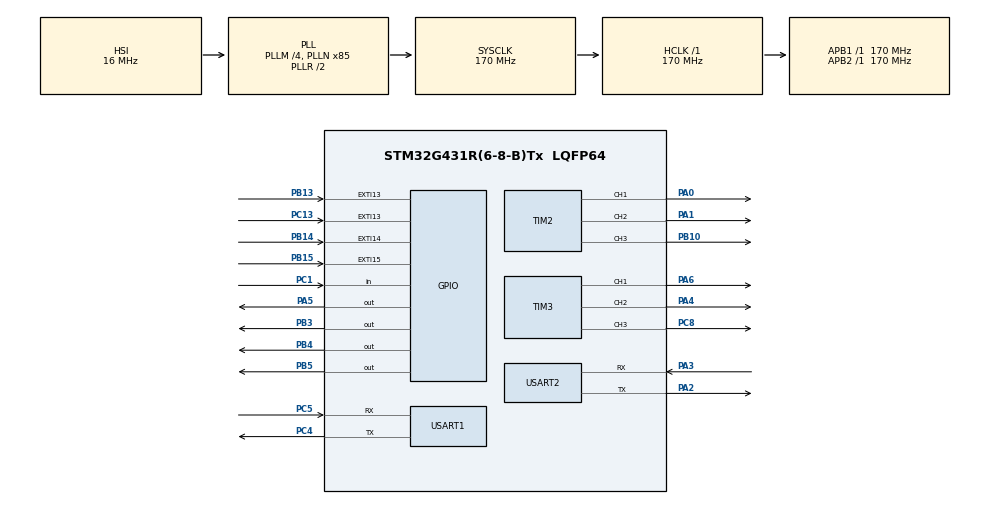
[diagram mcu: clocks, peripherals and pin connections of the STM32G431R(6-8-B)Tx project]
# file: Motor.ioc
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Dma.Request0=USART1_TX
Dma.Request1=USART1_RX
Dma.USART1_RX.1.Direction=DMA_PERIPH_TO_MEMORY
Dma.USART1_RX.1.EventEnable=DISABLE
Dma.USART1_RX.1.Instance=DMA1_Channel2
Dma.USART1_RX.1.MemDataAlignment=DMA_MDATAALIGN_BYTE
Dma.USART1_RX.1.MemInc=DMA_MINC_ENABLE
Dma.USART1_RX.1.Mode=DMA_NORMAL
Dma.USART1_RX.1.PeriphDataAlignment=DMA_PDATAALIGN_BYTE
Dma.USART1_RX.1.PeriphInc=DMA_PINC_DISABLE
Dma.USART1_RX.1.Polarity=HAL_DMAMUX_REQ_GEN_RISING
Dma.USART1_RX.1.Priority=DMA_PRIORITY_LOW
Dma.USART1_RX.1.RequestNumber=1
Dma.USART1_RX.1.SignalID=NONE
Dma.USART1_RX.1.SyncEnable=DISABLE
Dma.USART1_RX.1.SyncPolarity=HAL_DMAMUX_SYNC_NO_EVENT
Dma.USART1_RX.1.SyncRequestNumber=1
Dma.USART1_RX.1.SyncSignalID=NONE
Dma.USART1_TX.0.Direction=DMA_MEMORY_TO_PERIPH
Dma.USART1_TX.0.EventEnable=DISABLE
Dma.USART1_TX.0.Instance=DMA1_Channel1
Dma.USART1_TX.0.MemDataAlignment=DMA_MDATAALIGN_BYTE
Dma.USART1_TX.0.MemInc=DMA_MINC_ENABLE
Dma.USART1_TX.0.Mode=DMA_NORMAL
Dma.USART1_TX.0.PeriphDataAlignment=DMA_PDATAALIGN_BYTE
Dma.USART1_TX.0.PeriphInc=DMA_PINC_DISABLE
Dma.USART1_TX.0.Polarity=HAL_DMAMUX_REQ_GEN_RISING
Dma.USART1_TX.0.Priority=DMA_PRIORITY_LOW
Dma.USART1_TX.0.RequestNumber=1
Dma.USART1_TX.0.SignalID=NONE
Dma.USART1_TX.0.SyncEnable=DISABLE
Dma.USART1_TX.0.SyncPolarity=HAL_DMAMUX_SYNC_NO_EVENT
Dma.USART1_TX.0.SyncRequestNumber=1
Dma.USART1_TX.0.SyncSignalID=NONE
Mcu.Family=STM32G4
Mcu.Name=STM32G431R(6-8-B)Tx
Mcu.Package=LQFP64
NUCLEO-G431RB.BUTTON=1
NUCLEO-G431RB.LD1=true
NUCLEO-G431RB.VCP=true
NVIC.DMA1_Channel1_IRQn=true\:0\:0\:false\:false\:true\:false\:true\:true
NVIC.DMA1_Channel2_IRQn=true\:0\:0\:false\:false\:true\:false\:true\:true
NVIC.EXTI15_10_IRQn=true\:0\:0\:false\:false\:true\:false\:true\:true
NVIC.PriorityGroup=NVIC_PRIORITYGROUP_4
NVIC.TIM2_IRQn=true\:0\:0\:false\:false\:true\:true\:true\:true
NVIC.TIM3_IRQn=true\:0\:0\:false\:false\:true\:true\:true\:true
NVIC.TIM6_DAC_IRQn=true\:0\:0\:false\:false\:true\:true\:true\:true
NVIC.USART1_IRQn=true\:0\:0\:false\:false\:true\:true\:true\:true
PA0.Signal=S_TIM2_CH1
PA1.Signal=S_TIM2_CH2
PA13.GPIO_Label=T_SWDIO
PA13.Signal=SYS_JTMS-SWDIO
PA14.GPIO_Label=T_SWCLK
PA14.Signal=SYS_JTCK-SWCLK
PA2.Mode=Asynchronous
PA2.Signal=USART2_TX
PA3.Mode=Asynchronous
PA3.Signal=USART2_RX
PA4.Signal=S_TIM3_CH2
PA5.Signal=GPIO_Output
PA6.Signal=S_TIM3_CH1
PB10.Signal=S_TIM2_CH3
PB13.GPIO_ModeDefaultEXTI=GPIO_MODE_IT_RISING_FALLING
PB13.GPIO_PuPd=GPIO_PULLUP
PB13.Signal=GPXTI13
PB14.GPIO_ModeDefaultEXTI=GPIO_MODE_IT_RISING_FALLING
PB14.GPIO_PuPd=GPIO_PULLUP
PB14.Signal=GPXTI14
PB15.GPIO_ModeDefaultEXTI=GPIO_MODE_IT_RISING_FALLING
PB15.GPIO_PuPd=GPIO_PULLUP
PB15.Signal=GPXTI15
PB3.Signal=GPIO_Output
PB4.Signal=GPIO_Output
PB5.Signal=GPIO_Output
PC1.Signal=GPIO_Input
PC13.Signal=GPXTI13
PC14-OSC32_IN.GPIO_Label=RCC_OSC32_OUT
PC14-OSC32_IN.Signal=RCC_OSC32_IN
PC15-OSC32_OUT.GPIO_Label=RCC_OSC32_OUT
PC15-OSC32_OUT.Signal=RCC_OSC32_OUT
PC4.Mode=Asynchronous
PC4.Signal=USART1_TX
PC5.Mode=Asynchronous
PC5.Signal=USART1_RX
PC8.Signal=S_TIM3_CH3
PF0-OSC_IN.GPIO_Label=RCC_OSC_IN
PF0-OSC_IN.Signal=RCC_OSC_IN
PF1-OSC_OUT.GPIO_Label=RCC_OSC_OUT
PF1-OSC_OUT.Signal=RCC_OSC_OUT
ProjectManager.HeapSize=0x200
ProjectManager.StackSize=0x400
ProjectManager.TargetToolchain=MDK-ARM V5
RCC.ADC12Freq_Value=170000000
RCC.AHBFreq_Value=170000000
RCC.APB1Freq_Value=170000000
RCC.APB1TimFreq_Value=170000000
RCC.APB2Freq_Value=170000000
RCC.APB2TimFreq_Value=170000000
RCC.CortexFreq_Value=170000000
RCC.EXTERNAL_CLOCK_VALUE=12288000
RCC.HCLKFreq_Value=170000000
RCC.HSE_VALUE=24000000
RCC.HSI48_VALUE=48000000
RCC.HSI_VALUE=16000000
RCC.LSE_VALUE=32768
RCC.PLLM=RCC_PLLM_DIV4
RCC.PLLN=85
RCC.PLLQ=RCC_PLLQ_DIV4
RCC.RTCClockSelection=RCC_RTCCLKSOURCE_LSE
RCC.SYSCLKFreq_VALUE=170000000
RCC.SYSCLKSource=RCC_SYSCLKSOURCE_PLLCLK
RCC.USBFreq_Value=85000000
RCC.VCOOutputFreq_Value=340000000
SH.S_TIM2_CH1.0=TIM2_CH1,PWM Generation1 CH1
SH.S_TIM2_CH2.0=TIM2_CH2,PWM Generation2 CH2
SH.S_TIM2_CH3.0=TIM2_CH3,PWM Generation3 CH3
SH.S_TIM3_CH1.0=TIM3_CH1,PWM Generation1 CH1
SH.S_TIM3_CH2.0=TIM3_CH2,PWM Generation2 CH2
SH.S_TIM3_CH3.0=TIM3_CH3,PWM Generation3 CH3
TIM2.Channel-PWM\ Generation1\ CH1=TIM_CHANNEL_1
TIM2.Channel-PWM\ Generation2\ CH2=TIM_CHANNEL_2
TIM2.Channel-PWM\ Generation3\ CH3=TIM_CHANNEL_3
TIM2.PeriodNoDither=TIM2_AUTORELOAD
TIM2.Prescaler=APB1_TIM_CLOCK
TIM3.Channel-PWM\ Generation1\ CH1=TIM_CHANNEL_1
TIM3.Channel-PWM\ Generation2\ CH2=TIM_CHANNEL_2
TIM3.Channel-PWM\ Generation3\ CH3=TIM_CHANNEL_3
TIM3.PeriodNoDither=TIM3_AUTORELOAD
TIM3.Prescaler=APB1_TIM_CLOCK
TIM6.AutoReloadPreload=TIM_AUTORELOAD_PRELOAD_DISABLE
TIM6.PeriodNoDither=TIM6_AUTORELOAD
TIM6.Prescaler=APB1_TIM_CLOCK
USART1.BaudRate=USART1_BAUDRATE
USART1.VirtualMode-Asynchronous=VM_ASYNC
VP_NUCLEO-G431RB_VS_BSP_COMMON.Mode=COMMON
VP_SYS_VS_DBSignals.Mode=DisableDeadBatterySignals
VP_TIM6_VS_ClockSourceINT.Mode=Enable_Timer
board=NUCLEO-G431RB

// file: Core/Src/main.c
/* USER CODE BEGIN Header */
/**
  ******************************************************************************
  * @file           : main.c
  * @brief          : Main program body
  ******************************************************************************
  * @attention
  *
  * Copyright (c) 2024 STMicroelectronics.
  * All rights reserved.
  *
  * This software is licensed under terms that can be found in the LICENSE file
  * in the root directory of this software component.
  * If no LICENSE file comes with this software, it is provided AS-IS.
  *
  ******************************************************************************
  */
/* USER CODE END Header */
#include "main.h"
#include "dma.h"
#include "tim.h"
#include "usart.h"
#include "gpio.h"

COM_InitTypeDef BspCOMInit;

void SystemClock_Config(void);

int main(void)
{

  /* MCU Configuration--------------------------------------------------------*/

  /* Reset of all peripherals, Initializes the Flash interface and the Systick. */
  HAL_Init();

  /* Configure the system clock */
  SystemClock_Config();

  /* Initialize all configured peripherals */
  MX_GPIO_Init();
  MX_DMA_Init();
  MX_TIM2_Init();
  MX_TIM3_Init();
  MX_TIM6_Init();
  MX_USART1_UART_Init();

  /* Initialize leds */
  BSP_LED_Init(LED_GREEN);

  /* Initialize USER push-button, will be used to trigger an interrupt each time it's pressed.*/
  BSP_PB_Init(BUTTON_USER, BUTTON_MODE_EXTI);

  /* Initialize COM1 port (115200, 8 bits (7-bit data + 1 stop bit), no parity */
  BspCOMInit.BaudRate   = 115200;
  BspCOMInit.WordLength = COM_WORDLENGTH_8B;
  BspCOMInit.StopBits   = COM_STOPBITS_1;
  BspCOMInit.Parity     = COM_PARITY_NONE;
  BspCOMInit.HwFlowCtl  = COM_HWCONTROL_NONE;
  if (BSP_COM_Init(COM1, &BspCOMInit) != BSP_ERROR_NONE)
  {
    Error_Handler();
  }

  /* Infinite loop */
  /* USER CODE BEGIN WHILE */
  HYCodes_Init();
  HYCodes_Main();
  while (1)
  {

    /* USER CODE END WHILE */

  }
}

void SystemClock_Config(void)
{
  RCC_OscInitTypeDef RCC_OscInitStruct = {0};
  RCC_ClkInitTypeDef RCC_ClkInitStruct = {0};

  /** Configure the main internal regulator output voltage
  */
  HAL_PWREx_ControlVoltageScaling(PWR_REGULATOR_VOLTAGE_SCALE1_BOOST);

  /** Initializes the RCC Oscillators according to the specified parameters
  * in the RCC_OscInitTypeDef structure.
  */
  RCC_OscInitStruct.OscillatorType = RCC_OSCILLATORTYPE_HSI;
  RCC_OscInitStruct.HSIState = RCC_HSI_ON;
  RCC_OscInitStruct.HSICalibrationValue = RCC_HSICALIBRATION_DEFAULT;
  RCC_OscInitStruct.PLL.PLLState = RCC_PLL_ON;
  RCC_OscInitStruct.PLL.PLLSource = RCC_PLLSOURCE_HSI;
  RCC_OscInitStruct.PLL.PLLM = RCC_PLLM_DIV4;
  RCC_OscInitStruct.PLL.PLLN = 85;
  RCC_OscInitStruct.PLL.PLLP = RCC_PLLP_DIV2;
  RCC_OscInitStruct.PLL.PLLQ = RCC_PLLQ_DIV4;
  RCC_OscInitStruct.PLL.PLLR = RCC_PLLR_DIV2;
  if (HAL_RCC_OscConfig(&RCC_OscInitStruct) != HAL_OK)
  {
    Error_Handler();
  }

  /** Initializes the CPU, AHB and APB buses clocks
  */
  RCC_ClkInitStruct.ClockType = RCC_CLOCKTYPE_HCLK|RCC_CLOCKTYPE_SYSCLK
                              |RCC_CLOCKTYPE_PCLK1|RCC_CLOCKTYPE_PCLK2;
  RCC_ClkInitStruct.SYSCLKSource = RCC_SYSCLKSOURCE_PLLCLK;
  RCC_ClkInitStruct.AHBCLKDivider = RCC_SYSCLK_DIV1;
  RCC_ClkInitStruct.APB1CLKDivider = RCC_HCLK_DIV1;
  RCC_ClkInitStruct.APB2CLKDivider = RCC_HCLK_DIV1;

  if (HAL_RCC_ClockConfig(&RCC_ClkInitStruct, FLASH_LATENCY_4) != HAL_OK)
  {
    Error_Handler();
  }
}

void Error_Handler(void)
{
  __disable_irq();
  while (1)
  {
  }
}
